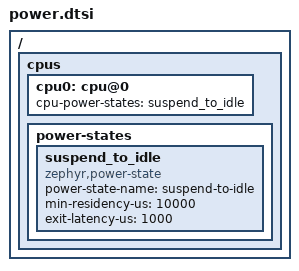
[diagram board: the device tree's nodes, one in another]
/ {
	cpus {
		cpu0: cpu@0 {
			cpu-power-states = <&suspend_to_idle>;
		};

		power-states {
			suspend_to_idle: suspend_to_idle {
				compatible = "zephyr,power-state";
				power-state-name = "suspend-to-idle";
				min-residency-us = <10000>;
				exit-latency-us = <1000>;
			};
		};
	};
};
